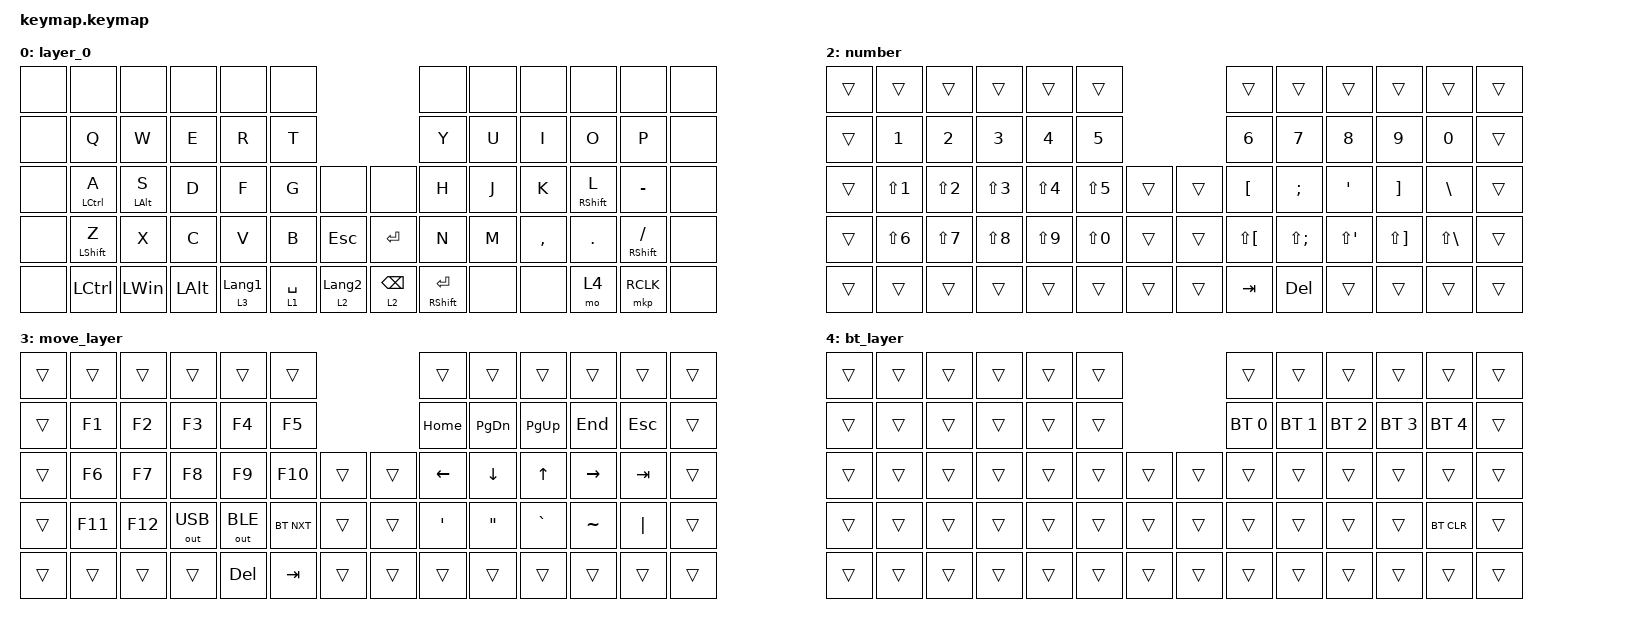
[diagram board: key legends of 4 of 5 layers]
#include <behaviors.dtsi>
#include <dt-bindings/zmk/bt.h>
#include <dt-bindings/zmk/keys.h>
#include <dt-bindings/zmk/outputs.h>
#include <dt-bindings/zmk/pointing.h>

/ {
    combos {
        compatible = "zmk,combos";

        bt_clear {
            bindings = <&bt BT_CLR>;
            key-positions = <28 29>;
            layers = <2>;
        };
    };

    behaviors {
        hrm: home_row_mods {
            compatible = "zmk,behavior-hold-tap";
            label = "HRM";
            #binding-cells = <2>;

            tapping-term-ms = <280>;
            quick-tap-ms = <175>;
            require-prior-idle-ms = <150>;
            flavor = "balanced";

            bindings = <&kp>, <&kp>;
        };
    };

    keymap {
        compatible = "zmk,keymap";

        layer_0 {
            bindings = <
&none  &none               &none           &none     &none     &none                           &none                  &none  &none      &none              &none                  &none
&none  &kp Q               &kp W           &kp E     &kp R     &kp T                           &kp Y                  &kp U  &kp I      &kp O              &kp P                  &none
&none  &hrm LEFT_CONTROL A &hrm LEFT_ALT S &kp D     &kp F     &kp G        &none  &none        &kp H                  &kp J  &kp K      &hrm RIGHT_SHIFT L  &kp MINUS              &none
&none  &hrm LEFT_SHIFT Z   &kp X           &kp C     &kp V     &kp B        &kp ESCAPE &kp RET  &kp N                  &kp M  &kp COMMA  &kp DOT            &hrm RIGHT_SHIFT SLASH &none
&none  &kp LCTRL           &kp LEFT_WIN    &kp LALT  &lt 3 LANGUAGE_1 &lt 1 SPACE &lt 2 LANGUAGE_2  &lt 2 BACKSPACE  &hrm RIGHT_SHIFT ENTER  &none  &none      &mo 4              &mkp RCLK              &none
            >;
        };
        
        mouse {
            bindings = <
        &trans  &trans      &trans        &trans         &trans     &trans                     &trans                &trans                 &trans           &trans         &trans             &trans
        
        /* 左手：ショートカット */
        &trans  &kp LC(A)   &kp LC(X)     &kp LC(C)      &kp LC(V)  &kp LC(F)                  &kp LESS_THAN         &kp GREATER_THAN       &kp CARET        &kp PERCENT    &kp DOLLAR         &trans
        
        /* 中央：マウス操作 */
        &trans  &kp TAB     &kp LEFT_ALT  &kp LS(TAB)    &mkp LCLK  &mkp RCLK  &trans  &trans  
        
        /* 右手：記号（JIS最適化） */
                &kp LEFT_BRACKET    /* @ */
                &kp RIGHT_BRACKET   /* [ */
                &kp BACKSLASH       /* ] */
                &kp SEMICOLON       /* + */
                &kp SINGLE_QUOTE    /* : */
                &trans
        
        /* 下段：補助 */
        &trans  &kp LSHIFT  &kp EQUAL     &kp BACKSLASH  &kp PIPE   &trans     &trans  &trans  
        
                &kp LS(LEFT_BRACKET)  /* ` */
                &kp LS(RIGHT_BRACKET) /* { */
                &kp LS(BACKSLASH)     /* } */
                &kp EXCLAMATION
                &kp QUESTION
                &trans
        
        &trans  &kp LCTRL   &trans        &trans         &trans     &trans     &trans  &trans  &trans &trans &trans &trans &trans
            >;
        };

        number {
            bindings = <
&trans  &trans        &trans        &trans      &trans      &trans                      &trans          &trans         &trans            &trans             &trans         &trans
&trans  &kp N1        &kp N2        &kp N3      &kp N4      &kp N5                      &kp N6          &kp N7         &kp N8            &kp N9             &kp N0         &trans

/* Shift系：! " # $ % */
&trans  &kp LS(N1)    &kp LS(N2)    &kp LS(N3)  &kp LS(N4)  &kp LS(N5)  &trans  &trans  

/* 記号（JIS最適化） */
        &kp LEFT_BRACKET   /* @ */
        &kp SEMICOLON      /* + */
        &kp SINGLE_QUOTE   /* : */
        &kp RIGHT_BRACKET  /* [ */
        &kp BACKSLASH      /* ] */
        &trans

/* 上段Shift系 */
&trans  &kp LS(N6)    &kp LS(N7)    &kp LS(N8)  &kp LS(N9)  &kp LS(N0)  &trans  &trans  

        &kp LS(LEFT_BRACKET)   /* ` */
        &kp LS(SEMICOLON)      /* * */
        &kp LS(SINGLE_QUOTE)   /* ; */
        &kp LS(RIGHT_BRACKET)  /* { */
        &kp LS(BACKSLASH)      /* } */
        &trans

&trans  &trans        &trans        &trans      &trans      &trans      &trans  &trans  &kp TAB  &kp DEL  &trans &trans &trans &trans
            >;
        };

        move_layer {
            bindings = <
&trans  &trans   &trans   &trans        &trans        &trans                      &trans            &trans         &trans        &trans     &trans      &trans
&trans  &kp F1   &kp F2   &kp F3        &kp F4        &kp F5                      &kp HOME          &kp PAGE_DOWN  &kp PAGE_UP   &kp END    &kp ESCAPE  &trans
&trans  &kp F6   &kp F7   &kp F8        &kp F9        &kp F10     &trans  &trans  &kp LEFT          &kp DOWN       &kp UP_ARROW  &kp RIGHT  &kp TAB     &trans
&trans  &kp F11  &kp F12  &out OUT_USB  &out OUT_BLE  &bt BT_NXT  &trans  &trans  &kp SINGLE_QUOTE  &kp DQT        &kp GRAVE     &kp TILDE  &kp PIPE    &trans
&trans  &trans   &trans   &trans        &kp DELETE    &kp TAB     &trans  &trans  &trans            &trans         &trans        &trans     &trans      &trans
            >;
        };

        bt_layer {
            bindings = <
&trans  &trans  &trans  &trans  &trans  &trans                  &trans        &trans        &trans        &trans        &trans        &trans
&trans  &trans  &trans  &trans  &trans  &trans                  &bt BT_SEL 0  &bt BT_SEL 1  &bt BT_SEL 2  &bt BT_SEL 3  &bt BT_SEL 4  &trans
&trans  &trans  &trans  &trans  &trans  &trans  &trans  &trans  &trans        &trans        &trans        &trans        &trans        &trans
&trans  &trans  &trans  &trans  &trans  &trans  &trans  &trans  &trans        &trans        &trans        &trans        &bt BT_CLR    &trans
&trans  &trans  &trans  &trans  &trans  &trans  &trans  &trans  &trans        &trans        &trans        &trans        &trans        &trans
            >;
        };
    };
};
